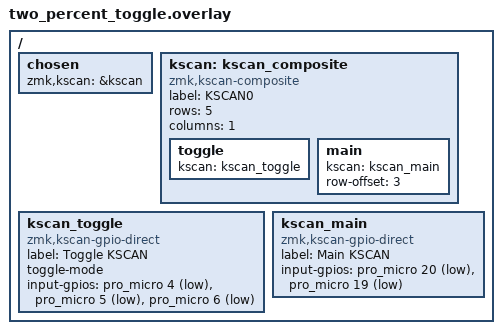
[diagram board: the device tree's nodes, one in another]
/*
 * Copyright (c) 2022 The ZMK Contributors
 *
 * SPDX-License-Identifier: MIT
 */

/ {
	chosen {
		zmk,kscan = &kscan;
	};

    kscan: kscan_composite {
		compatible = "zmk,kscan-composite";
		label = "KSCAN0";
        rows = <5>;
        columns = <1>;

        toggle {
            kscan = <&kscan_toggle>;
        };

        main {
            kscan = <&kscan_main>;
            row-offset = <3>;
        };
	};

	kscan_toggle: kscan_toggle {
		compatible = "zmk,kscan-gpio-direct";
		label = "Toggle KSCAN";
        toggle-mode;
		input-gpios
			= <&pro_micro 4 GPIO_ACTIVE_LOW>
			, <&pro_micro 5 GPIO_ACTIVE_LOW>
            , <&pro_micro 6 GPIO_ACTIVE_LOW>
			;

	};

    kscan_main: kscan_main {
	    compatible = "zmk,kscan-gpio-direct";
		label = "Main KSCAN";
		input-gpios
			= <&pro_micro 20 (GPIO_ACTIVE_LOW | GPIO_PULL_UP)>
			, <&pro_micro 19 (GPIO_ACTIVE_LOW | GPIO_PULL_UP)>
			;

	};

};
